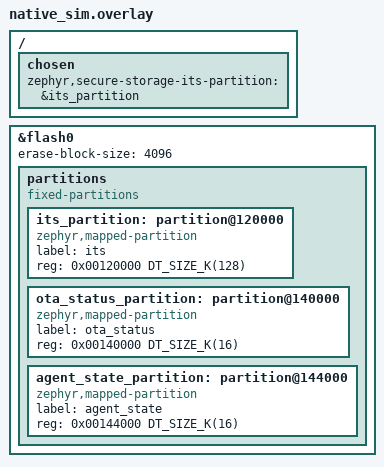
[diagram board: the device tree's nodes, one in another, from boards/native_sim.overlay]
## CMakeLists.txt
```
# Copyright 2026 NXP
#
# SPDX-License-Identifier: Apache-2.0
#

cmake_minimum_required(VERSION 3.20.0)
find_package(Zephyr REQUIRED HINTS $ENV{ZEPHYR_BASE})
project(el2go_ota_agent_component)

add_compile_definitions(ENABLE_TRACE)

set(CT_ROOT ${ZEPHYR_NXP_IOT_AGENT_MODULE_DIR}/tests/component)
set(ADV_AGENT_MAIN ${ZEPHYR_NXP_IOT_AGENT_MODULE_DIR}/applications/ota_agents/el2go_ota_agent_advanced/src/main.c)

target_sources(app PRIVATE
    ${CMAKE_CURRENT_SOURCE_DIR}/src/ztest_agent_component_main.c
    ${ADV_AGENT_MAIN}
    ${ZEPHYR_NXP_IOT_AGENT_MODULE_DIR}/applications/ota_agents/el2go_ota_agent_advanced/src/updater.c
    ${ZEPHYR_NXP_IOT_AGENT_MODULE_DIR}/applications/ota_agents/el2go_ota_agent_advanced/src/scheduler.c
    ${ZEPHYR_NXP_IOT_AGENT_MODULE_DIR}/applications/ota_agents/el2go_ota_agent_advanced/src/policy.c
    ${ZEPHYR_NXP_IOT_AGENT_MODULE_DIR}/tests/unit/mock/el2go_ota_lib_mock.c
    ${ZEPHYR_NXP_IOT_AGENT_MODULE_DIR}/tests/unit/mock/fwual_mock.c
    ${ZEPHYR_NXP_IOT_AGENT_MODULE_DIR}/tests/unit/mock/wrap_app_sys.c
    ${ZEPHYR_NXP_IOT_AGENT_MODULE_DIR}/tests/unit/mock/agent_test_fixtures.c
    ${CT_ROOT}/internal_ota_agent_core/test_el2go_ota_agent_core_internal_zephyr.c
    ${CT_ROOT}/public_ota_agent_core/test_el2go_ota_agent_core_public_zephyr.c
    ${CT_ROOT}/internal_ota_agent_advanced/test_el2go_ota_agent_advanced_internal_zephyr.c
    ${CT_ROOT}/public_ota_agent_advanced/test_el2go_ota_agent_advanced_public_zephyr.c
    ${CT_ROOT}/common/agent_component_fixtures.c
    ${CMAKE_CURRENT_SOURCE_DIR}/boards/native_sim/test_backend.c
)

target_compile_definitions(app PRIVATE OTA_FW_VERSION="0.0.0-test")

set_source_files_properties(
    ${ADV_AGENT_MAIN}
    PROPERTIES COMPILE_DEFINITIONS "main=el2go_ota_agent_advanced_main_unused"
)

zephyr_ld_options(
    -Wl,--wrap=el2go_ota_init
    -Wl,--wrap=el2go_ota_connect
    -Wl,--wrap=el2go_ota_disconnect
    -Wl,--wrap=el2go_ota_cleanup
    -Wl,--wrap=el2go_ota_is_connected
    -Wl,--wrap=el2go_ota_get_error_string
    -Wl,--wrap=el2go_ota_check_for_updates
    -Wl,--wrap=el2go_ota_download_package
    -Wl,--wrap=el2go_ota_report_status
    -Wl,--wrap=el2go_ota_schedule_status_report
    -Wl,--wrap=el2go_ota_get_pending_status
    -Wl,--wrap=el2go_ota_report_pending_status
    -Wl,--wrap=el2go_app_sys_activate_update
    -Wl,--wrap=el2go_app_sys_sleep_ms
    -Wl,--wrap=el2go_app_sys_uptime_ms
    -Wl,--wrap=el2go_app_sys_wait
    -Wl,--wrap=el2go_app_sys_signal
    -Wl,--wrap=el2go_app_time_get_hour_of_day
    -Wl,--wrap=el2go_app_time_sync
)

zephyr_include_directories(
    ${ZEPHYR_NXP_IOT_AGENT_MODULE_DIR}/tests/unit/mock
    ${CT_ROOT}/framework
    ${CT_ROOT}/common
    ${CT_ROOT}/internal_ota_agent_core
    ${CT_ROOT}/public_ota_agent_core
    ${CT_ROOT}/internal_ota_agent_advanced
    ${CT_ROOT}/public_ota_agent_advanced
    ${ZEPHYR_NXP_IOT_AGENT_MODULE_DIR}/applications/ota_agents
    ${ZEPHYR_NXP_IOT_AGENT_MODULE_DIR}/applications/ota_agents/el2go_ota_agent_advanced/include
    ${ZEPHYR_NXP_IOT_AGENT_MODULE_DIR}/applications/ota_agents/common/diag
    ${ZEPHYR_NXP_IOT_AGENT_MODULE_DIR}/applications/ota_agents/common/persist
    ${ZEPHYR_NXP_IOT_AGENT_MODULE_DIR}/applications/ota_agents/common/event
    ${ZEPHYR_NXP_IOT_AGENT_MODULE_DIR}/applications/common/system
    ${ZEPHYR_NXP_IOT_AGENT_MODULE_DIR}/applications/common/time
    ${ZEPHYR_NXP_IOT_AGENT_MODULE_DIR}/applications/common/network
    ${ZEPHYR_NXP_IOT_AGENT_MODULE_DIR}/include
    ${ZEPHYR_NXP_IOT_AGENT_MODULE_DIR}/priv
    ${ZEPHYR_NXP_IOT_AGENT_MODULE_DIR}/libs/protobuf/nanopb
    ${ZEPHYR_NXP_IOT_AGENT_MODULE_DIR}/libs/el2go_ota_lib/src
    ${ZEPHYR_NXP_IOT_AGENT_MODULE_DIR}/libs/protobuf/ota
)

zephyr_include_directories(
    ${ZEPHYR_BASE}/../modules/crypto/tf-psa-crypto/include
    ${ZEPHYR_BASE}/../modules/crypto/tf-psa-crypto/drivers/builtin/include
    ${ZEPHYR_BASE}/../modules/crypto/mbedtls/include
    ${ZEPHYR_BASE}/subsys/secure_storage/include
    ${ZEPHYR_NXP_IOT_AGENT_MODULE_DIR}/libs/net_crypto
    ${ZEPHYR_NXP_IOT_AGENT_MODULE_DIR}/libs/platforms
)
```

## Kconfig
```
# Copyright 2026 NXP
# SPDX-License-Identifier: Apache-2.0

source "Kconfig.zephyr"
```

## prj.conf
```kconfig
# Copyright 2026 NXP
# SPDX-License-Identifier: Apache-2.0

CONFIG_EL2GO_OTA_FWUAL_LIBRARY_SOURCES=y
CONFIG_EL2GO_OTA_LIBRARY_SOURCES=y
# CONFIG_EL2GO_OTA_PLATFORM_SOURCES is intentionally not set
CONFIG_EL2GO_OTA_TESTS=y

CONFIG_EL2GO_OTA_DIAG_SOURCES=y

CONFIG_EL2GO_OTA_EVENT_SOURCES=y
CONFIG_EL2GO_SYSTEM_SOURCES=y
CONFIG_EL2GO_TIME_SOURCES=y

CONFIG_EL2GO_OTA_PERSIST_SOURCES=y
CONFIG_EL2GO_OTA_PERSIST_BACKEND_NVS=y

CONFIG_PRINTK=y
CONFIG_ZTEST=y

CONFIG_COMPILER_WARNINGS_AS_ERRORS=n

CONFIG_PSA_CRYPTO=y
CONFIG_MBEDTLS=y
CONFIG_MBEDTLS_BUILTIN=y
CONFIG_MBEDTLS_PSA_CRYPTO_C=y
CONFIG_MBEDTLS_ENABLE_HEAP=y
CONFIG_MBEDTLS_HEAP_SIZE=65536
CONFIG_MBEDTLS_SSL_PROTO_TLS1_2=y
CONFIG_MBEDTLS_SSL_IN_CONTENT_LEN=16384
CONFIG_MBEDTLS_SSL_OUT_CONTENT_LEN=16384
CONFIG_MBEDTLS_SSL_ALPN=y
CONFIG_MBEDTLS_X509_CRT_WRITE_C=y
CONFIG_MBEDTLS_X509_CSR_WRITE_C=y
CONFIG_MBEDTLS_PK_WRITE_C=y
CONFIG_MBEDTLS_X509_CRT_PARSE_C=y
CONFIG_MBEDTLS_ASN1_PARSE_C=y
CONFIG_MBEDTLS_SSL_SERVER_NAME_INDICATION=y
CONFIG_MBEDTLS_KEY_EXCHANGE_ECDHE_ECDSA_ENABLED=y

CONFIG_PSA_CRYPTO_ENABLE_ALL=y
CONFIG_PSA_WANT_ALG_ECDSA=y
CONFIG_PSA_WANT_ALG_ECDH=y
CONFIG_PSA_WANT_ALG_SHA_256=y
CONFIG_PSA_WANT_ALG_SHA_384=y
CONFIG_PSA_WANT_ALG_GCM=y
CONFIG_PSA_WANT_ECC_SECP_R1_256=y
CONFIG_PSA_WANT_KEY_TYPE_AES=y

CONFIG_SECURE_STORAGE=y
CONFIG_ZMS=y
CONFIG_SECURE_STORAGE_ITS_STORE_IMPLEMENTATION_ZMS=y

CONFIG_FLASH=y
CONFIG_FLASH_MAP=y
CONFIG_FLASH_PAGE_LAYOUT=y
CONFIG_FLASH_SIMULATOR=y
CONFIG_NVS=y
CONFIG_MPU_ALLOW_FLASH_WRITE=y

CONFIG_NETWORKING=y
CONFIG_NET_IPV4=y
CONFIG_NET_TCP=y
CONFIG_NET_SOCKETS=y

CONFIG_REQUIRES_FULL_LIBC=y
CONFIG_POSIX_API=y
CONFIG_HEAP_MEM_POOL_SIZE=131072
CONFIG_MAIN_STACK_SIZE=16384
CONFIG_ZTEST_STACK_SIZE=16384
CONFIG_HWINFO=y

CONFIG_EL2GO_OTA_POLL_INTERVAL_S=30
CONFIG_EL2GO_OTA_ADV_POLL_INTERVAL_S=30
CONFIG_EL2GO_OTA_ADV_DOWNLOAD_MAX_RETRIES=4
CONFIG_EL2GO_OTA_ADV_REPORT_MAX_RETRIES=4
CONFIG_EL2GO_OTA_ADV_RETRY_INITIAL_BACKOFF_S=1
CONFIG_EL2GO_OTA_ADV_RETRY_MAX_BACKOFF_S=8
CONFIG_EL2GO_OTA_ADV_BLACKOUT_START_HOUR=22
CONFIG_EL2GO_OTA_ADV_BLACKOUT_END_HOUR=6
CONFIG_EL2GO_OTA_ADV_DEFER_WINDOW_S=30
```

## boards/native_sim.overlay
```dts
/*
 * Copyright 2026 NXP
 *
 * SPDX-License-Identifier: Apache-2.0
 */

/ {
    chosen {
        zephyr,secure-storage-its-partition = &its_partition;
    };
};

&flash0 {
    erase-block-size = <4096>;
    partitions {
        compatible = "fixed-partitions";
        #address-cells = <1>;
        #size-cells = <1>;

        its_partition: partition@120000 {
            compatible = "zephyr,mapped-partition";
            label = "its";
            reg = <0x00120000 DT_SIZE_K(128)>;
        };

        ota_status_partition: partition@140000 {
            compatible = "zephyr,mapped-partition";
            label = "ota_status";
            reg = <0x00140000 DT_SIZE_K(16)>;
        };

        agent_state_partition: partition@144000 {
            compatible = "zephyr,mapped-partition";
            label = "agent_state";
            reg = <0x00144000 DT_SIZE_K(16)>;
        };
    };
};
```

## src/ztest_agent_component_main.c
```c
/*
 * Copyright 2026 NXP
 *
 * SPDX-License-Identifier: Apache-2.0
 *
 */

#include <zephyr/ztest.h>

#include "test_ztest.h"

#include "test_el2go_ota_agent_core_internal_zephyr.h"
#include "test_el2go_ota_agent_core_public_zephyr.h"
#include "test_el2go_ota_agent_advanced_internal_zephyr.h"
#include "test_el2go_ota_agent_advanced_public_zephyr.h"

ZTEST_SUITE(el2go_agent_ct, NULL, NULL, NULL, NULL, NULL);

TEST_ZTEST_SUITE(el2go_agent_ct, ota_agent_core_internal)
TEST_ZTEST_SUITE(el2go_agent_ct, ota_agent_core_public)
TEST_ZTEST_SUITE(el2go_agent_ct, ota_agent_advanced_internal)
TEST_ZTEST_SUITE(el2go_agent_ct, ota_agent_advanced_public)
```
